# STM32MP153 register map
File version: 1.3
CPU: CM4 r0p1, little endian, no MPU, FPU, 4 interrupt priority bits
Registers are 32-bit, read-write, reset 0x0 unless marked. A register's access mark holds for its fields unless they carry their own. Offsets are from the block's base; [hi:lo] are bit positions; {n}, {i} and the like mark numbered series.

## TIM1
Base 0x44000000
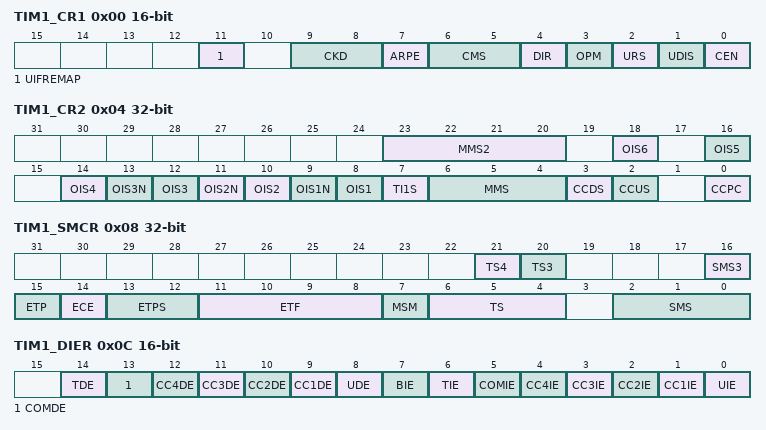
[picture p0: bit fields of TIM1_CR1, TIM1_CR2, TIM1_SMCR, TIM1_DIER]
0x00 TIM1_CR1 16-bit — TIM1 control register 1
  [11] UIFREMAP, [9:8] CKD, [7] ARPE, [6:5] CMS, [4] DIR, [3] OPM, [2] URS, [1] UDIS, [0] CEN
0x04 TIM1_CR2 — TIM1 control register 2
  [23:20] MMS2, [2n+6] OIS{n} (n=1..6), [13] OIS3N, [11] OIS2N, [9] OIS1N, [7] TI1S, [6:4] MMS, [3] CCDS, [2] CCUS, [0] CCPC
0x08 TIM1_SMCR — TIM1 slave mode control register
  [21] TS4, [20] TS3, [16] SMS3, [15] ETP, [14] ECE, [13:12] ETPS, [11:8] ETF, [7] MSM, [6:4] TS, [2:0] SMS
0x0C TIM1_DIER 16-bit — TIM1 DMA/interrupt enable register
  [14] TDE, [13] COMDE, [n+8] CC{n}DE (n=1..4), [8] UDE, [7] BIE, [6] TIE, [5] COMIE, [n] CC{n}IE (n=1..4), [0] UIE
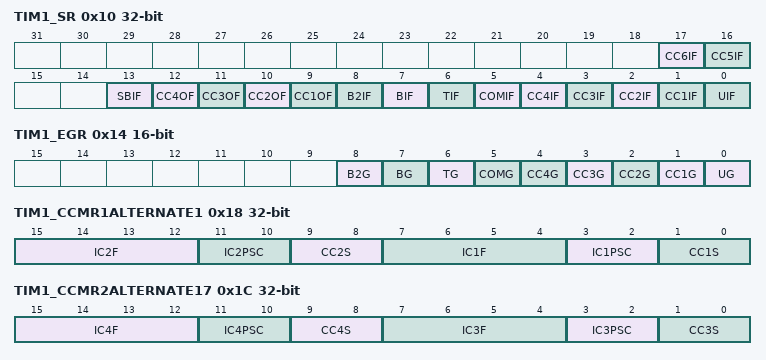
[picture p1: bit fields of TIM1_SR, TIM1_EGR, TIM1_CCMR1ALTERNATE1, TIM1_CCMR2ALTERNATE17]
0x10 TIM1_SR — TIM1 status register
  [17] CC6IF, [16] CC5IF, [13] SBIF, [n+8] CC{n}OF (n=1..4), [8] B2IF, [7] BIF, [6] TIF, [5] COMIF, [n] CC{n}IF (n=1..4), [0] UIF
0x14 TIM1_EGR 16-bit wo — TIM1 event generation register
  [8] B2G, [7] BG, [6] TG, [5] COMG, [n] CC{n}G (n=1..4), [0] UG
0x18 TIM1_CCMR1ALTERNATE1 — The same register can be used for input capture mode (this section) or for output compare mode (next section). The direction of a channel is defined by configuring the corresponding CCxS bits. All the other bits of this register have a different function for input capture and for output compare modes. It is possible to combine both modes independently (e.g. channel 1 in input capture mode and channel 2 in output compare mode). Input capture mode:
  [15:12] IC2F, [11:10] IC2PSC, [9:8] CC2S, [7:4] IC1F, [3:2] IC1PSC, [1:0] CC1S
0x1C TIM1_CCMR2ALTERNATE17 — The same register can be used for input capture mode (this section) or for output compare mode (next section). The direction of a channel is defined by configuring the corresponding CCxS bits. All the other bits of this register have a different function for input capture and for output compare modes. It is possible to combine both modes independently (e.g. channel 1 in input capture mode and channel 2 in output compare mode). Input capture mode:
  [15:12] IC4F, [11:10] IC4PSC, [9:8] CC4S, [7:4] IC3F, [3:2] IC3PSC, [1:0] CC3S
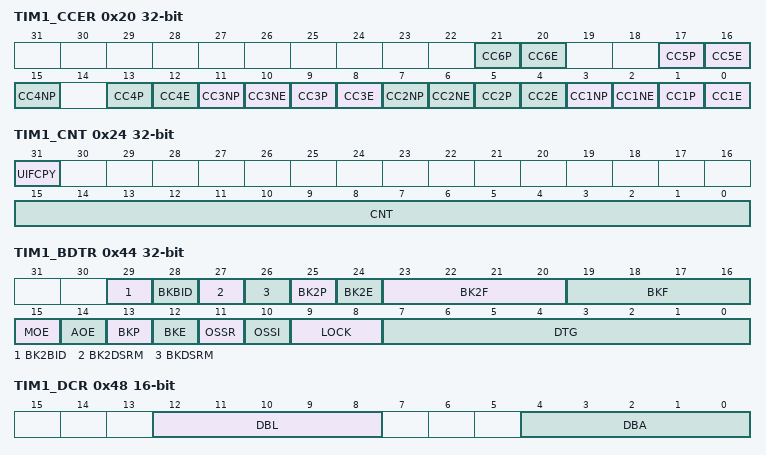
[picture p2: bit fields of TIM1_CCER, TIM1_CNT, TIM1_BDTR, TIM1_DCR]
0x20 TIM1_CCER — TIM1 capture/compare enable register
  [4n-3] CC{n}P (n=1..6), [4n-4] CC{n}E (n=1..6), [4n-1] CC{n}NP (n=1..4), [10] CC3NE, [6] CC2NE, [2] CC1NE
0x24 TIM1_CNT access per field — TIM1 counter
  [31] UIFCPY ro, [15:0] CNT rw
0x28 TIM1_PSC 16-bit — TIM1 prescaler
0x2C TIM1_ARR 16-bit reset 0xFFFF — TIM1 auto-reload register
0x30 TIM1_RCR 16-bit — TIM1 repetition counter register
  [15:0] REP
{0x30+4i} TIM1_CCR{i} 16-bit (i=1..4) — TIM1 capture/compare register {i}
0x44 TIM1_BDTR — As the bits BK2BID, BKBID, BK2DSRM, BKDSRM, BK2P, BK2E, BK2F[3:0], BKF[3:0], AOE, BKP, BKE, OSSI, OSSR and DTG[7:0] can be write-locked depending on the LOCK configuration, it can be necessary to configure all of them during the first write access to the TIMx_BDTR register.
  [29] BK2BID, [28] BKBID, [27] BK2DSRM, [26] BKDSRM, [25] BK2P, [24] BK2E, [23:20] BK2F, [19:16] BKF, [15] MOE, [14] AOE, [13] BKP, [12] BKE, [11] OSSR, [10] OSSI, [9:8] LOCK, [7:0] DTG
0x48 TIM1_DCR 16-bit — TIM1 DMA control register
  [12:8] DBL, [4:0] DBA
0x4C TIM1_DMAR — TIM1 DMA address for full transfer
  [31:0] DMAB
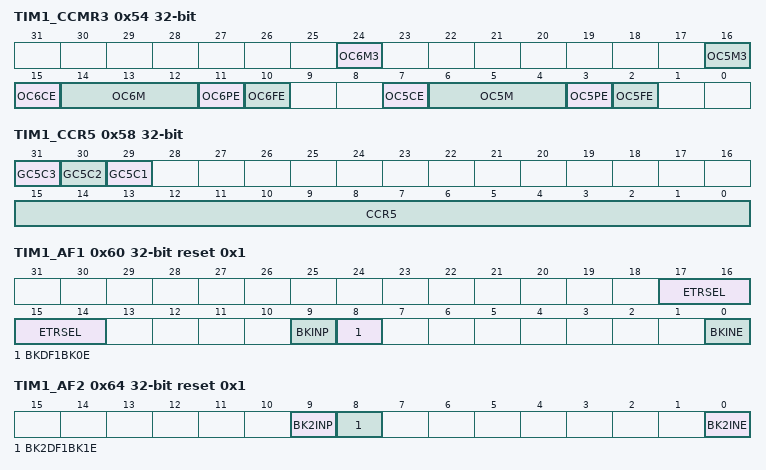
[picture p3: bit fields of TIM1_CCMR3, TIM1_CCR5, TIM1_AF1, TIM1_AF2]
0x54 TIM1_CCMR3 — The channels 5 and 6 can only be configured in output. Output compare mode:
  [24] OC6M3, [16] OC5M3, [15] OC6CE, [14:12] OC6M, [11] OC6PE, [10] OC6FE, [7] OC5CE, [6:4] OC5M, [3] OC5PE, [2] OC5FE
0x58 TIM1_CCR5 — TIM1 capture/compare register 5
  [31] GC5C3, [30] GC5C2, [29] GC5C1, [15:0] CCR5
0x5C TIM1_CCR6 16-bit — TIM1 capture/compare register 6
0x60 TIM1_AF1 reset 0x1 — TIM1 alternate function option register 1
  [17:14] ETRSEL, [9] BKINP, [8] BKDF1BK0E, [0] BKINE
0x64 TIM1_AF2 reset 0x1 — TIM1 Alternate function register 2
  [9] BK2INP, [8] BK2DF1BK1E, [0] BK2INE
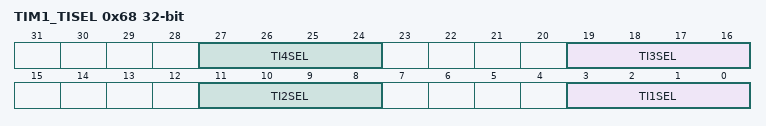
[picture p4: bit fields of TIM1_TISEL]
0x68 TIM1_TISEL — TIM1 timer input selection register
  [8n-5:8n-8] TI{n}SEL (n=1..4)

## TIM2
Base 0x40000000
Registers as TIM1 (with TIM1 read as TIM2), without TIM1_CCMR1ALTERNATE1, TIM1_CCMR2ALTERNATE17, TIM1_AF1, TIM1_AF2, TIM1_TISEL; these are added or differ:
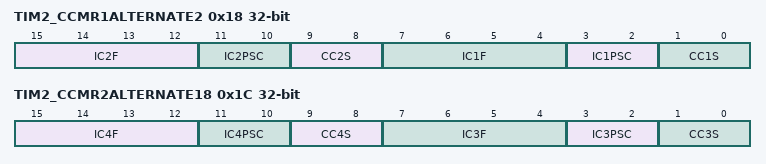
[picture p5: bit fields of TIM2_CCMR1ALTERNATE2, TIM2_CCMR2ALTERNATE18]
0x18 TIM2_CCMR1ALTERNATE2 — The same register can be used for input capture mode (this section) or for output compare mode (next section). The direction of a channel is defined by configuring the corresponding CCxS bits. All the other bits of this register have a different function for input capture and for output compare modes. It is possible to combine both modes independently (e.g. channel 1 in input capture mode and channel 2 in output compare mode). Input capture mode:
  [15:12] IC2F, [11:10] IC2PSC, [9:8] CC2S, [7:4] IC1F, [3:2] IC1PSC, [1:0] CC1S
0x1C TIM2_CCMR2ALTERNATE18 — The same register can be used for input capture mode (this section) or for output compare mode (next section). The direction of a channel is defined by configuring the corresponding CCxS bits. All the other bits of this register have a different function for input capture and for output compare modes. It is possible to combine both modes independently (e.g. channel 1 in input capture mode and channel 2 in output compare mode). Input capture mode:
  [15:12] IC4F, [11:10] IC4PSC, [9:8] CC4S, [7:4] IC3F, [3:2] IC3PSC, [1:0] CC3S

## TIM3
Base 0x40001000
Registers as TIM1 (with TIM1 read as TIM3), without TIM1_CCMR1ALTERNATE1, TIM1_CCMR2ALTERNATE17, TIM1_AF1, TIM1_AF2, TIM1_TISEL; these are added or differ:
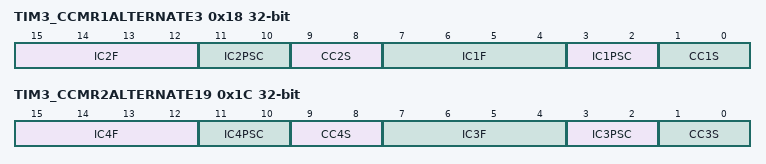
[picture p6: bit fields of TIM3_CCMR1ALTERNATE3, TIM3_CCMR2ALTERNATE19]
0x18 TIM3_CCMR1ALTERNATE3 — The same register can be used for input capture mode (this section) or for output compare mode (next section). The direction of a channel is defined by configuring the corresponding CCxS bits. All the other bits of this register have a different function for input capture and for output compare modes. It is possible to combine both modes independently (e.g. channel 1 in input capture mode and channel 2 in output compare mode). Input capture mode:
  [15:12] IC2F, [11:10] IC2PSC, [9:8] CC2S, [7:4] IC1F, [3:2] IC1PSC, [1:0] CC1S
0x1C TIM3_CCMR2ALTERNATE19 — The same register can be used for input capture mode (this section) or for output compare mode (next section). The direction of a channel is defined by configuring the corresponding CCxS bits. All the other bits of this register have a different function for input capture and for output compare modes. It is possible to combine both modes independently (e.g. channel 1 in input capture mode and channel 2 in output compare mode). Input capture mode:
  [15:12] IC4F, [11:10] IC4PSC, [9:8] CC4S, [7:4] IC3F, [3:2] IC3PSC, [1:0] CC3S

## TIM4
Base 0x40002000
Registers as TIM1 (with TIM1 read as TIM4), without TIM1_CCMR1ALTERNATE1, TIM1_CCMR2ALTERNATE17, TIM1_AF1, TIM1_AF2, TIM1_TISEL; these are added or differ:
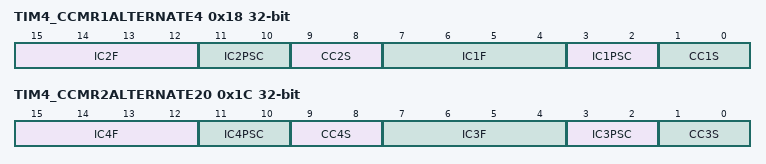
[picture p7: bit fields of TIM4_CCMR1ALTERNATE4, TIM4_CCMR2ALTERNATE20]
0x18 TIM4_CCMR1ALTERNATE4 — The same register can be used for input capture mode (this section) or for output compare mode (next section). The direction of a channel is defined by configuring the corresponding CCxS bits. All the other bits of this register have a different function for input capture and for output compare modes. It is possible to combine both modes independently (e.g. channel 1 in input capture mode and channel 2 in output compare mode). Input capture mode:
  [15:12] IC2F, [11:10] IC2PSC, [9:8] CC2S, [7:4] IC1F, [3:2] IC1PSC, [1:0] CC1S
0x1C TIM4_CCMR2ALTERNATE20 — The same register can be used for input capture mode (this section) or for output compare mode (next section). The direction of a channel is defined by configuring the corresponding CCxS bits. All the other bits of this register have a different function for input capture and for output compare modes. It is possible to combine both modes independently (e.g. channel 1 in input capture mode and channel 2 in output compare mode). Input capture mode:
  [15:12] IC4F, [11:10] IC4PSC, [9:8] CC4S, [7:4] IC3F, [3:2] IC3PSC, [1:0] CC3S

## TIM5
Base 0x40003000
Registers as TIM1 (with TIM1 read as TIM5), without TIM1_CCMR1ALTERNATE1, TIM1_CCMR2ALTERNATE17, TIM1_AF1, TIM1_AF2, TIM1_TISEL; these are added or differ:
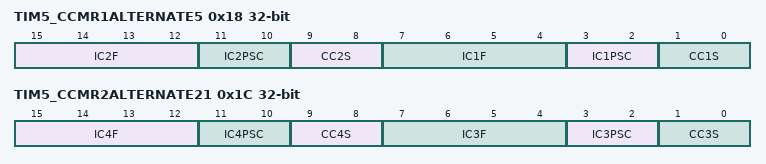
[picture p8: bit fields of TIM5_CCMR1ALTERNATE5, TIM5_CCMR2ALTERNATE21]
0x18 TIM5_CCMR1ALTERNATE5 — The same register can be used for input capture mode (this section) or for output compare mode (next section). The direction of a channel is defined by configuring the corresponding CCxS bits. All the other bits of this register have a different function for input capture and for output compare modes. It is possible to combine both modes independently (e.g. channel 1 in input capture mode and channel 2 in output compare mode). Input capture mode:
  [15:12] IC2F, [11:10] IC2PSC, [9:8] CC2S, [7:4] IC1F, [3:2] IC1PSC, [1:0] CC1S
0x1C TIM5_CCMR2ALTERNATE21 — The same register can be used for input capture mode (this section) or for output compare mode (next section). The direction of a channel is defined by configuring the corresponding CCxS bits. All the other bits of this register have a different function for input capture and for output compare modes. It is possible to combine both modes independently (e.g. channel 1 in input capture mode and channel 2 in output compare mode). Input capture mode:
  [15:12] IC4F, [11:10] IC4PSC, [9:8] CC4S, [7:4] IC3F, [3:2] IC3PSC, [1:0] CC3S

## TIM6
Base 0x40004000
Registers as TIM1 (with TIM1 read as TIM6), without TIM1_CCMR1ALTERNATE1, TIM1_CCMR2ALTERNATE17, TIM1_AF1, TIM1_AF2, TIM1_TISEL; these are added or differ:
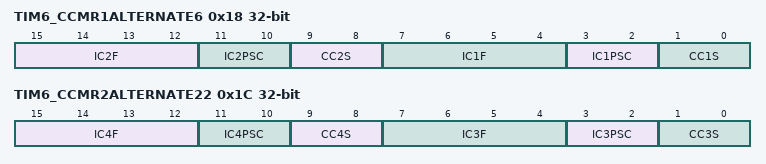
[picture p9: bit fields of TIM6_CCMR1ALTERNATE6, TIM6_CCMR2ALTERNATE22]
0x18 TIM6_CCMR1ALTERNATE6 — The same register can be used for input capture mode (this section) or for output compare mode (next section). The direction of a channel is defined by configuring the corresponding CCxS bits. All the other bits of this register have a different function for input capture and for output compare modes. It is possible to combine both modes independently (e.g. channel 1 in input capture mode and channel 2 in output compare mode). Input capture mode:
  [15:12] IC2F, [11:10] IC2PSC, [9:8] CC2S, [7:4] IC1F, [3:2] IC1PSC, [1:0] CC1S
0x1C TIM6_CCMR2ALTERNATE22 — The same register can be used for input capture mode (this section) or for output compare mode (next section). The direction of a channel is defined by configuring the corresponding CCxS bits. All the other bits of this register have a different function for input capture and for output compare modes. It is possible to combine both modes independently (e.g. channel 1 in input capture mode and channel 2 in output compare mode). Input capture mode:
  [15:12] IC4F, [11:10] IC4PSC, [9:8] CC4S, [7:4] IC3F, [3:2] IC3PSC, [1:0] CC3S

## TIM7
Base 0x40005000
Registers as TIM1 (with TIM1 read as TIM7), without TIM1_CCMR1ALTERNATE1, TIM1_CCMR2ALTERNATE17, TIM1_AF1, TIM1_AF2, TIM1_TISEL; these are added or differ:
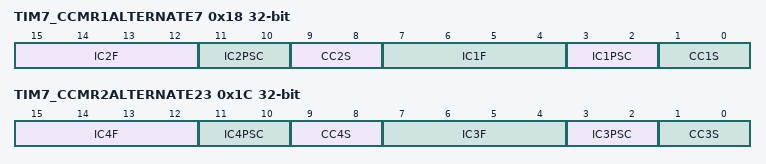
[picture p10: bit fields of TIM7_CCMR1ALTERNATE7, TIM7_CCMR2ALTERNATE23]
0x18 TIM7_CCMR1ALTERNATE7 — The same register can be used for input capture mode (this section) or for output compare mode (next section). The direction of a channel is defined by configuring the corresponding CCxS bits. All the other bits of this register have a different function for input capture and for output compare modes. It is possible to combine both modes independently (e.g. channel 1 in input capture mode and channel 2 in output compare mode). Input capture mode:
  [15:12] IC2F, [11:10] IC2PSC, [9:8] CC2S, [7:4] IC1F, [3:2] IC1PSC, [1:0] CC1S
0x1C TIM7_CCMR2ALTERNATE23 — The same register can be used for input capture mode (this section) or for output compare mode (next section). The direction of a channel is defined by configuring the corresponding CCxS bits. All the other bits of this register have a different function for input capture and for output compare modes. It is possible to combine both modes independently (e.g. channel 1 in input capture mode and channel 2 in output compare mode). Input capture mode:
  [15:12] IC4F, [11:10] IC4PSC, [9:8] CC4S, [7:4] IC3F, [3:2] IC3PSC, [1:0] CC3S

## TIM8
Base 0x44001000
Registers as TIM1 (with TIM1 read as TIM8), without TIM1_CCMR1ALTERNATE1, TIM1_CCMR2ALTERNATE17; these are added or differ:
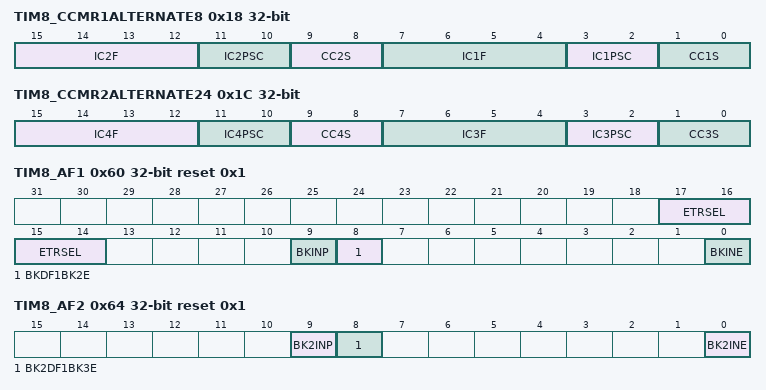
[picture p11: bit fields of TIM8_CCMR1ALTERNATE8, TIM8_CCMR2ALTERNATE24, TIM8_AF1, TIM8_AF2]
0x18 TIM8_CCMR1ALTERNATE8 — The same register can be used for input capture mode (this section) or for output compare mode (next section). The direction of a channel is defined by configuring the corresponding CCxS bits. All the other bits of this register have a different function for input capture and for output compare modes. It is possible to combine both modes independently (e.g. channel 1 in input capture mode and channel 2 in output compare mode). Input capture mode:
  [15:12] IC2F, [11:10] IC2PSC, [9:8] CC2S, [7:4] IC1F, [3:2] IC1PSC, [1:0] CC1S
0x1C TIM8_CCMR2ALTERNATE24 — The same register can be used for input capture mode (this section) or for output compare mode (next section). The direction of a channel is defined by configuring the corresponding CCxS bits. All the other bits of this register have a different function for input capture and for output compare modes. It is possible to combine both modes independently (e.g. channel 1 in input capture mode and channel 2 in output compare mode). Input capture mode:
  [15:12] IC4F, [11:10] IC4PSC, [9:8] CC4S, [7:4] IC3F, [3:2] IC3PSC, [1:0] CC3S
0x60 TIM8_AF1 reset 0x1 — TIM8 Alternate function option register 1
  [17:14] ETRSEL, [9] BKINP, [8] BKDF1BK2E, [0] BKINE
0x64 TIM8_AF2 reset 0x1 — TIM8 Alternate function option register 2
  [9] BK2INP, [8] BK2DF1BK3E, [0] BK2INE
